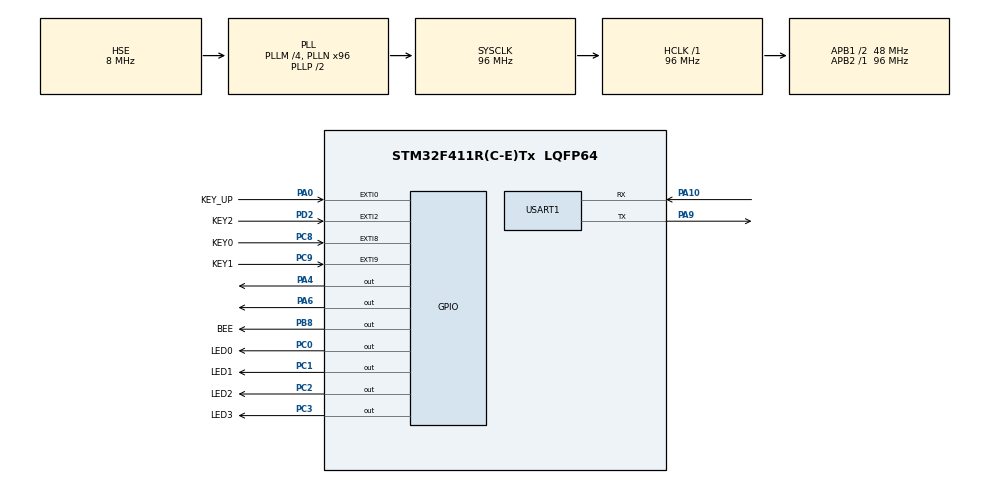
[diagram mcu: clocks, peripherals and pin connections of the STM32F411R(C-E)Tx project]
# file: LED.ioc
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Mcu.Family=STM32F4
Mcu.Name=STM32F411R(C-E)Tx
Mcu.Package=LQFP64
NVIC.EXTI0_IRQn=true\:2\:2\:true\:false\:true\:true\:true\:true
NVIC.EXTI2_IRQn=true\:2\:1\:true\:false\:true\:true\:true\:true
NVIC.EXTI9_5_IRQn=true\:2\:0\:true\:false\:true\:true\:true\:true
NVIC.PriorityGroup=NVIC_PRIORITYGROUP_2
NVIC.USART1_IRQn=true\:0\:0\:false\:false\:true\:true\:true\:true
PA0-WKUP.GPIO_Label=KEY_UP
PA0-WKUP.GPIO_ModeDefaultEXTI=GPIO_MODE_IT_RISING
PA0-WKUP.GPIO_PuPd=GPIO_PULLDOWN
PA0-WKUP.Signal=GPXTI0
PA10.Mode=Asynchronous
PA10.Signal=USART1_RX
PA4.GPIO_PuPd=GPIO_NOPULL
PA4.PinState=GPIO_PIN_SET
PA4.Signal=GPIO_Output
PA6.GPIO_PuPd=GPIO_NOPULL
PA6.PinState=GPIO_PIN_SET
PA6.Signal=GPIO_Output
PA9.Mode=Asynchronous
PA9.Signal=USART1_TX
PB8.GPIO_Label=BEE
PB8.GPIO_PuPd=GPIO_NOPULL
PB8.GPIO_Speed=GPIO_SPEED_FREQ_LOW
PB8.PinState=GPIO_PIN_SET
PB8.Signal=GPIO_Output
PC0.GPIO_Label=LED0
PC0.GPIO_PuPd=GPIO_PULLUP
PC0.GPIO_Speed=GPIO_SPEED_FREQ_HIGH
PC0.PinState=GPIO_PIN_SET
PC0.Signal=GPIO_Output
PC1.GPIO_Label=LED1
PC1.GPIO_ModeDefaultOutputPP=GPIO_MODE_OUTPUT_PP
PC1.GPIO_PuPd=GPIO_PULLUP
PC1.GPIO_Speed=GPIO_SPEED_FREQ_HIGH
PC1.PinState=GPIO_PIN_SET
PC1.Signal=GPIO_Output
PC2.GPIO_Label=LED2
PC2.GPIO_PuPd=GPIO_PULLUP
PC2.GPIO_Speed=GPIO_SPEED_FREQ_HIGH
PC2.PinState=GPIO_PIN_SET
PC2.Signal=GPIO_Output
PC3.GPIO_Label=LED3
PC3.GPIO_PuPd=GPIO_PULLUP
PC3.GPIO_Speed=GPIO_SPEED_FREQ_HIGH
PC3.PinState=GPIO_PIN_SET
PC3.Signal=GPIO_Output
PC8.GPIO_Label=KEY0
PC8.GPIO_ModeDefaultEXTI=GPIO_MODE_IT_FALLING
PC8.GPIO_PuPd=GPIO_PULLUP
PC8.Signal=GPXTI8
PC9.GPIO_Label=KEY1
PC9.GPIO_ModeDefaultEXTI=GPIO_MODE_IT_FALLING
PC9.GPIO_PuPd=GPIO_PULLUP
PC9.Signal=GPXTI9
PD2.GPIO_Label=KEY2
PD2.GPIO_ModeDefaultEXTI=GPIO_MODE_IT_FALLING
PD2.GPIO_PuPd=GPIO_PULLUP
PD2.Signal=GPXTI2
PH0\ -\ OSC_IN.Mode=HSE-External-Oscillator
PH0\ -\ OSC_IN.Signal=RCC_OSC_IN
PH1\ -\ OSC_OUT.Mode=HSE-External-Oscillator
PH1\ -\ OSC_OUT.Signal=RCC_OSC_OUT
ProjectManager.HeapSize=0x200
ProjectManager.StackSize=0x400
ProjectManager.TargetToolchain=MDK-ARM V5
RCC.48MHZClocksFreq_Value=48000000
RCC.AHBFreq_Value=96000000
RCC.APB1CLKDivider=RCC_HCLK_DIV2
RCC.APB1Freq_Value=48000000
RCC.APB1TimFreq_Value=96000000
RCC.APB2Freq_Value=96000000
RCC.APB2TimFreq_Value=96000000
RCC.CortexFreq_Value=96000000
RCC.HCLKFreq_Value=96000000
RCC.HSE_VALUE=8000000
RCC.HSI_VALUE=16000000
RCC.LSE_VALUE=32768
RCC.PLLM=4
RCC.PLLN=96
RCC.PLLSourceVirtual=RCC_PLLSOURCE_HSE
RCC.SYSCLKFreq_VALUE=96000000
RCC.SYSCLKSource=RCC_SYSCLKSOURCE_PLLCLK
RCC.VCOOutputFreq_Value=192000000
USART1.VirtualMode=VM_ASYNC
board=custom

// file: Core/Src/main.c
/* USER CODE BEGIN Header */
/**
  ******************************************************************************
  * @file           : main.c
  * @brief          : Main program body
  ******************************************************************************
  * @attention
  *
  * <h2><center>&copy; Copyright (c) 2023 STMicroelectronics.
  * All rights reserved.</center></h2>
  *
  * This software component is licensed by ST under BSD 3-Clause license,
  * the "License"; You may not use this file except in compliance with the
  * License. You may obtain a copy of the License at:
  *                        opensource.org/licenses/BSD-3-Clause
  *
  ******************************************************************************
  */
/* USER CODE END Header */
#include "main.h"

/* USER CODE BEGIN Includes */
#include <usart.h>
#include <exit.h>
#include <led.h>
#include <oled.h>
/* USER CODE END Includes */

UART_HandleTypeDef huart1;

void SystemClock_Config(void);
static void MX_GPIO_Init(void);
static void MX_USART1_UART_Init(void);

/* USER CODE BEGIN 0 */
/* user define    */
 uint8_t rx_data[2];

/*user fun*/
//void HAL_UART_RxCpltCallback(UART_HandleTypeDef *huart);
//int fgetc(FILE *f);
//int fputc(int ch, FILE *f);
/* USER CODE END 0 */

int main(void)
{

  /* MCU Configuration--------------------------------------------------------*/

  /* Reset of all peripherals, Initializes the Flash interface and the Systick. */
  HAL_Init();

  /* USER CODE BEGIN Init */
  OLED_Init();
	OLED_Clear();
  /* USER CODE END Init */

  /* Configure the system clock */
  SystemClock_Config();

  /* Initialize all configured peripherals */
  MX_GPIO_Init();
  MX_USART1_UART_Init();
  /* USER CODE BEGIN 2 */

  printf("stm32 is ready\n");
	//LED1_ON();
  uint8_t data[] = {'A','P'};
  HAL_UART_Receive_IT(&huart1,rx_data, 2);
  //printf("send a data\n");
	//LED2_ON();
  /* USER CODE END 2 */

  /* Infinite loop */
  while (1)
  {

    /* USER CODE BEGIN 3 */
      LED2_SHIE();
    //OLED_ShowString(8,4,(uint8_t *)"ASD",16); //表示x=4，y=8开始显示字符串
    //printf("send a data\n");
    //OLED_ShowChar(8,6,48/10,16);     //显示一个字符

    //注意10,16);字符串和字符的子函数不一样!!!!!!!!!!!!!!

  }
  /* USER CODE END 3 */
}

void SystemClock_Config(void)
{
  RCC_OscInitTypeDef RCC_OscInitStruct = {0};
  RCC_ClkInitTypeDef RCC_ClkInitStruct = {0};

  /** Configure the main internal regulator output voltage
  */
  __HAL_RCC_PWR_CLK_ENABLE();
  __HAL_PWR_VOLTAGESCALING_CONFIG(PWR_REGULATOR_VOLTAGE_SCALE1);

  /** Initializes the RCC Oscillators according to the specified parameters
  * in the RCC_OscInitTypeDef structure.
  */
  RCC_OscInitStruct.OscillatorType = RCC_OSCILLATORTYPE_HSE;
  RCC_OscInitStruct.HSEState = RCC_HSE_ON;
  RCC_OscInitStruct.PLL.PLLState = RCC_PLL_ON;
  RCC_OscInitStruct.PLL.PLLSource = RCC_PLLSOURCE_HSE;
  RCC_OscInitStruct.PLL.PLLM = 4;
  RCC_OscInitStruct.PLL.PLLN = 96;
  RCC_OscInitStruct.PLL.PLLP = RCC_PLLP_DIV2;
  RCC_OscInitStruct.PLL.PLLQ = 4;
  if (HAL_RCC_OscConfig(&RCC_OscInitStruct) != HAL_OK)
  {
    Error_Handler();
  }

  /** Initializes the CPU, AHB and APB buses clocks
  */
  RCC_ClkInitStruct.ClockType = RCC_CLOCKTYPE_HCLK|RCC_CLOCKTYPE_SYSCLK
                              |RCC_CLOCKTYPE_PCLK1|RCC_CLOCKTYPE_PCLK2;
  RCC_ClkInitStruct.SYSCLKSource = RCC_SYSCLKSOURCE_PLLCLK;
  RCC_ClkInitStruct.AHBCLKDivider = RCC_SYSCLK_DIV1;
  RCC_ClkInitStruct.APB1CLKDivider = RCC_HCLK_DIV2;
  RCC_ClkInitStruct.APB2CLKDivider = RCC_HCLK_DIV1;

  if (HAL_RCC_ClockConfig(&RCC_ClkInitStruct, FLASH_LATENCY_3) != HAL_OK)
  {
    Error_Handler();
  }
}

static void MX_USART1_UART_Init(void)
{

  huart1.Instance = USART1;
  huart1.Init.BaudRate = 115200;
  huart1.Init.WordLength = UART_WORDLENGTH_8B;
  huart1.Init.StopBits = UART_STOPBITS_1;
  huart1.Init.Parity = UART_PARITY_NONE;
  huart1.Init.Mode = UART_MODE_TX_RX;
  huart1.Init.HwFlowCtl = UART_HWCONTROL_NONE;
  huart1.Init.OverSampling = UART_OVERSAMPLING_16;
  if (HAL_UART_Init(&huart1) != HAL_OK)
  {
    Error_Handler();
  }

}

static void MX_GPIO_Init(void)
{
  GPIO_InitTypeDef GPIO_InitStruct = {0};

  /* GPIO Ports Clock Enable */
  __HAL_RCC_GPIOH_CLK_ENABLE();
  __HAL_RCC_GPIOC_CLK_ENABLE();
  __HAL_RCC_GPIOA_CLK_ENABLE();
  __HAL_RCC_GPIOD_CLK_ENABLE();
  __HAL_RCC_GPIOB_CLK_ENABLE();

  /*Configure GPIO pin Output Level */
  HAL_GPIO_WritePin(GPIOC, LED0_Pin|LED1_Pin|LED2_Pin|LED3_Pin, GPIO_PIN_SET);

  /*Configure GPIO pin Output Level */
  HAL_GPIO_WritePin(GPIOA, GPIO_PIN_4|GPIO_PIN_6, GPIO_PIN_SET);

  /*Configure GPIO pin Output Level */
  HAL_GPIO_WritePin(BEE_GPIO_Port, BEE_Pin, GPIO_PIN_SET);

  /*Configure GPIO pins : LED0_Pin LED1_Pin LED2_Pin LED3_Pin */
  GPIO_InitStruct.Pin = LED0_Pin|LED1_Pin|LED2_Pin|LED3_Pin;
  GPIO_InitStruct.Mode = GPIO_MODE_OUTPUT_PP;
  GPIO_InitStruct.Pull = GPIO_PULLUP;
  GPIO_InitStruct.Speed = GPIO_SPEED_FREQ_HIGH;
  HAL_GPIO_Init(GPIOC, &GPIO_InitStruct);

  /*Configure GPIO pin : KEY_UP_Pin */
  GPIO_InitStruct.Pin = KEY_UP_Pin;
  GPIO_InitStruct.Mode = GPIO_MODE_IT_RISING;
  GPIO_InitStruct.Pull = GPIO_PULLDOWN;
  HAL_GPIO_Init(KEY_UP_GPIO_Port, &GPIO_InitStruct);

  /*Configure GPIO pins : PA4 PA6 */
  GPIO_InitStruct.Pin = GPIO_PIN_4|GPIO_PIN_6;
  GPIO_InitStruct.Mode = GPIO_MODE_OUTPUT_PP;
  GPIO_InitStruct.Pull = GPIO_NOPULL;
  GPIO_InitStruct.Speed = GPIO_SPEED_FREQ_LOW;
  HAL_GPIO_Init(GPIOA, &GPIO_InitStruct);

  /*Configure GPIO pins : KEY0_Pin KEY1_Pin */
  GPIO_InitStruct.Pin = KEY0_Pin|KEY1_Pin;
  GPIO_InitStruct.Mode = GPIO_MODE_IT_FALLING;
  GPIO_InitStruct.Pull = GPIO_PULLUP;
  HAL_GPIO_Init(GPIOC, &GPIO_InitStruct);

  /*Configure GPIO pin : KEY2_Pin */
  GPIO_InitStruct.Pin = KEY2_Pin;
  GPIO_InitStruct.Mode = GPIO_MODE_IT_FALLING;
  GPIO_InitStruct.Pull = GPIO_PULLUP;
  HAL_GPIO_Init(KEY2_GPIO_Port, &GPIO_InitStruct);

  /*Configure GPIO pin : BEE_Pin */
  GPIO_InitStruct.Pin = BEE_Pin;
  GPIO_InitStruct.Mode = GPIO_MODE_OUTPUT_PP;
  GPIO_InitStruct.Pull = GPIO_NOPULL;
  GPIO_InitStruct.Speed = GPIO_SPEED_FREQ_LOW;
  HAL_GPIO_Init(BEE_GPIO_Port, &GPIO_InitStruct);

  /* EXTI interrupt init*/
  HAL_NVIC_SetPriority(EXTI0_IRQn, 2, 2);
  HAL_NVIC_EnableIRQ(EXTI0_IRQn);

  HAL_NVIC_SetPriority(EXTI2_IRQn, 2, 1);
  HAL_NVIC_EnableIRQ(EXTI2_IRQn);

  HAL_NVIC_SetPriority(EXTI9_5_IRQn, 2, 0);
  HAL_NVIC_EnableIRQ(EXTI9_5_IRQn);

}

/* USER CODE BEGIN 4 */
/*int fputc(int ch, FILE *f)

{

  HAL_UART_Transmit(&huart1, (uint8_t *)&ch, 1, 0xffff);

  return ch;

}

int fgetc(FILE *f)

{

uint8_t ch;

// 采用轮询方式接收 1字节数据，超时时间设置为无限等待

HAL_UART_Receive( &huart1,(uint8_t*)&ch,1, HAL_MAX_DELAY );

return ch;
}

void HAL_UART_RxCpltCallback(UART_HandleTypeDef *huart)
{

   UNUSED(huart);
	if(huart->Instance ==USART1)
	{

		HAL_UART_Transmit_IT(&huart1,rx_data,2);
		if(rx_data[0] == 'a')
		{
			LED3_ON();
			HAL_UART_Receive_IT(&huart1, rx_data, 2);
		}

		if(rx_data[0] == 'b')
		{
			LED0_ON();
			HAL_UART_Receive_IT(&huart1, rx_data, 2);
		}
		if(rx_data[0] == 'c')
		{
			LED0_OFF();
			LED3_OFF();
			HAL_UART_Receive_IT(&huart1, rx_data, 2);
		}

	}
	HAL_UART_Receive_IT(&huart1, rx_data, 2);
} */
/* USER CODE END 4 */

void Error_Handler(void)
{
  __disable_irq();
  while (1)
  {
  }
}
